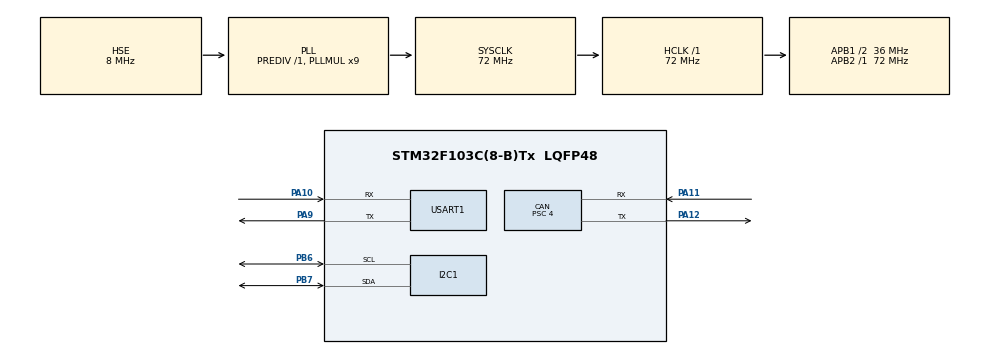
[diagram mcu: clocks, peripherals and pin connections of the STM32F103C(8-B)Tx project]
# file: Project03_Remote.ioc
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CAN.BS1=CAN_BS1_15TQ
CAN.BS2=CAN_BS2_2TQ
CAN.CalculateBaudRate=500000
CAN.CalculateTimeBit=2000
CAN.CalculateTimeQuantum=111.11111111111111
CAN.Prescaler=4
FREERTOS.Tasks01=defaultTask,0,128,StartDefaultTask,Default,NULL,Dynamic,NULL,NULL;CanRxTask,-3,256,StartCanRxTask,Default,NULL,Dynamic,NULL,NULL
FREERTOS.configTOTAL_HEAP_SIZE=6144
I2C1.I2C_Mode=I2C_Fast
Mcu.Family=STM32F1
Mcu.Name=STM32F103C(8-B)Tx
Mcu.Package=LQFP48
NVIC.PriorityGroup=NVIC_PRIORITYGROUP_4
NVIC.USB_LP_CAN1_RX0_IRQn=true\:5\:0\:false\:false\:true\:true\:true\:true\:true
PA10.Mode=Asynchronous
PA10.Signal=USART1_RX
PA11.Mode=CAN_Activate
PA11.Signal=CAN_RX
PA12.Mode=CAN_Activate
PA12.Signal=CAN_TX
PA13.Mode=Serial_Wire
PA13.Signal=SYS_JTMS-SWDIO
PA14.Mode=Serial_Wire
PA14.Signal=SYS_JTCK-SWCLK
PA9.Mode=Asynchronous
PA9.Signal=USART1_TX
PB6.Mode=I2C
PB6.Signal=I2C1_SCL
PB7.Mode=I2C
PB7.Signal=I2C1_SDA
PD0-OSC_IN.Mode=HSE-External-Oscillator
PD0-OSC_IN.Signal=RCC_OSC_IN
PD1-OSC_OUT.Mode=HSE-External-Oscillator
PD1-OSC_OUT.Signal=RCC_OSC_OUT
ProjectManager.HeapSize=0x200
ProjectManager.StackSize=0x400
ProjectManager.TargetToolchain=STM32CubeIDE
RCC.AHBFreq_Value=72000000
RCC.APB1CLKDivider=RCC_HCLK_DIV2
RCC.APB1Freq_Value=36000000
RCC.APB1TimFreq_Value=72000000
RCC.APB2Freq_Value=72000000
RCC.APB2TimFreq_Value=72000000
RCC.HCLKFreq_Value=72000000
RCC.PLLMUL=RCC_PLL_MUL9
RCC.PLLSourceVirtual=RCC_PLLSOURCE_HSE
RCC.SYSCLKFreq_VALUE=72000000
RCC.SYSCLKSource=RCC_SYSCLKSOURCE_PLLCLK
RCC.USBFreq_Value=72000000
USART1.VirtualMode=VM_ASYNC
VP_FREERTOS_VS_CMSIS_V1.Mode=CMSIS_V1
board=custom

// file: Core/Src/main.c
/* USER CODE BEGIN Header */
/**
  ******************************************************************************
  * @file           : main.c
  * @brief          : Main program body
  ******************************************************************************
  * @attention
  *
  * Copyright (c) 2026 STMicroelectronics.
  * All rights reserved.
  *
  * This software is licensed under terms that can be found in the LICENSE file
  * in the root directory of this software component.
  * If no LICENSE file comes with this software, it is provided AS-IS.
  *
  ******************************************************************************
  */
/* USER CODE END Header */
#include "main.h"
#include "cmsis_os.h"
#include "can.h"
#include "i2c.h"
#include "usart.h"
#include "gpio.h"

/* USER CODE BEGIN Includes */
#include <stdio.h>
/* USER CODE END Includes */

/* USER CODE BEGIN PD */
/* CAN 수신 원형 버퍼의 칸 수.
   인터럽트가 빠르게 받아 담아두고 태스크가 천천히 꺼내 가므로
   잠깐 몰리는 것만 견디면 되어 8칸이면 충분하다. */
#define CAN_RX_RING_SIZE   8u
/* USER CODE END PD */

/* USER CODE BEGIN PV */
/* ===== CAN 수신 원형 버퍼 =====
   수신 인터럽트(ISR)가 head 를 밀면서 쓰고,
   CanRxTask 가 tail 을 밀면서 읽는다.
   쓰는 쪽 하나, 읽는 쪽 하나뿐이므로(생산자 1 : 소비자 1)
   인터럽트를 잠그지 않아도 서로 충돌하지 않는다.
   인터럽트가 값을 바꾸는 변수들이므로 컴파일러가 레지스터에
   캐시해 두지 못하도록 전부 volatile 로 선언한다. */
static volatile CanRxFrame_t g_can_ring[CAN_RX_RING_SIZE];
static volatile uint16_t     g_can_head     = 0;  /* 인터럽트가 다음에 쓸 칸 */
static volatile uint16_t     g_can_tail     = 0;  /* 태스크가 다음에 읽을 칸 */
static volatile uint32_t     g_can_total    = 0;  /* 총 수신 개수 */
static volatile uint32_t     g_can_overflow = 0;  /* 버퍼가 꽉 차서 버린 개수 */

/* ===== 디버거 관찰용 진단 변수 (Live Expressions) =====
   USB-TTL 시리얼 어댑터가 없어 printf 출력을 볼 수 없을 때,
   STM32CubeIDE 의 Live Expressions 창(디버깅 중에 변수 값을 실시간으로 보는 기능)에
   아래 이름을 그대로 적어 넣으면 값이 보인다.

   주의 1) static 을 붙이지 않는다.
             static 은 "이 파일 안에서만 보이게 하라"는 뜻이라,
             디버거가 이름으로 변수를 못 찾는 경우가 생긴다.
   주의 2) volatile 은 반드시 붙인다.
             이것이 없으면 컴파일러가 "어차피 아무도 안 읽는 값"이라고 판단해
             대입 문장 자체를 지워버리거나 레지스터에만 담아두어
             메모리를 들여다보는 디버거에게는 엉뚱한 값이 보인다. */

/* I2C 스캔에서 응답한 장치 총 개수 */
volatile uint8_t  g_diag_i2c_found        = 0u;
/* 응답한 주소 목록 (최대 8개까지, 나머지 칸은 0) */
volatile uint8_t  g_diag_i2c_addr[8]      = {0u};
/* IMU 주소. 0x68 이 응답하면 0x68, 못 찾으면 0 */
volatile uint8_t  g_diag_imu_addr         = 0u;
/* WHO_AM_I(0x75) 레지스터에서 읽은 값. 못 읽으면 0xFF */
volatile uint8_t  g_diag_who_am_i         = 0xFFu;
/* 칩이 어떤 모델인지 판별한 결과 코드
     0 = 못 찾음
     1 = MPU-9250 (WHO_AM_I 값 0x71, 9축·나침반 있음)
     2 = MPU-9255 (WHO_AM_I 값 0x73, 9축·나침반 있음)
     3 = MPU-6500 (WHO_AM_I 값 0x70, 6축·나침반 없음)
     4 = MPU-6050 (WHO_AM_I 값 0x68, 6축·나침반 없음)
     9 = 알 수 없는 칩 */
volatile uint8_t  g_diag_imu_kind         = 0u;
/* I2C 스캔이 끝나면 1 이 된다 */
volatile uint8_t  g_diag_scan_done        = 0u;

/* CAN 총 수신 개수 */
volatile uint32_t g_diag_can_total        = 0u;
/* 마지막으로 받은 프레임의 ID */
volatile uint32_t g_diag_can_last_id      = 0u;
/* 마지막으로 받은 프레임의 데이터 길이 (0~8) */
volatile uint8_t  g_diag_can_last_dlc     = 0u;
/* 마지막으로 받은 프레임의 데이터 8바이트 */
volatile uint8_t  g_diag_can_last_data[8] = {0u};
/* 직전 1초 동안 받은 개수 */
volatile uint32_t g_diag_can_per_sec      = 0u;

/* ===== CAN 통신 장애 원인 판별용 진단 변수 =====
   수신이 전혀 안 될 때(g_diag_can_per_sec 가 계속 0),
   원인이 "MCU 안쪽 설정"인지 "바깥 배선·트랜시버·상대 노드"인지
   갈라내기 위한 값들이다. 전부 Live Expressions 로 관찰한다.
   앞의 진단 변수들과 같은 이유로 static 을 붙이지 않고 volatile 만 붙인다. */

/* HAL_CAN_Start() 가 성공해서 지금 정상 모드로 돌고 있으면 1, 아니면 0 */
volatile uint8_t  g_diag_can_started      = 0u;
/* 수신 필터 설정(HAL_CAN_ConfigFilter)이 성공했으면 1 */
volatile uint8_t  g_diag_can_filter_ok    = 0u;
/* 수신 인터럽트 켜기(HAL_CAN_ActivateNotification)가 성공했으면 1 */
volatile uint8_t  g_diag_can_notify_ok    = 0u;

/* ===== CAN_ESR(오류 상태 레지스터)에서 뽑아낸 값들 =====
   RM0008(STM32F1 참조매뉴얼)의 CAN_ESR 비트 배치는 다음과 같다.
     비트 31~24 : REC[7:0]  수신 오류 카운터
     비트 23~16 : TEC[7:0]  송신 오류 카운터
     비트  6~4  : LEC[2:0]  마지막 오류 코드
     비트  3    : (예약, 쓰지 않음)
     비트  2    : BOFF      버스오프 상태
     비트  1    : EPVF      오류 수동(Error Passive) 상태
     비트  0    : EWGF      오류 경고(Error Warning) 상태
   [확인 기록] 작업 지시서의 표에는 TEC 가 24~31비트, REC 가 16~23비트라고
   적혀 있었으나 이는 둘이 서로 뒤바뀐 것이다. RM0008 기준으로는 위가 맞다.
   그래서 값을 뽑아내는 코드도 TEC 는 16비트에서, REC 는 24비트에서
   잘라내도록 해 두었다(freertos.c 의 Can_UpdateErrorDiag 참고). */

/* 송신 오류 카운터 (ESR 비트 23~16).
   보낸 프레임이 실패할 때마다 8씩 오른다.
   아무도 응답(ACK)해 주지 않는 상황이면 순식간에 128 까지 치솟는다. */
volatile uint8_t  g_diag_can_tec          = 0u;
/* 수신 오류 카운터 (ESR 비트 31~24).
   받는 쪽에서 어긋난 프레임을 볼 때마다 오른다.
   상대가 아예 아무것도 안 보내면 이 값은 0 에서 그대로 멈춰 있다. */
volatile uint8_t  g_diag_can_rec          = 0u;
/* 마지막 오류 코드 (ESR 비트 6~4). 값의 뜻은 아래 표와 같다.
     0 = 오류 없음
     1 = 스터프 오류 (같은 값이 6비트 내리 나왔다.
                      두 노드의 통신 속도(보율)가 서로 다를 때 잘 난다)
     2 = 폼 오류     (프레임의 정해진 모양이 어긋났다)
     3 = ACK 오류    (응답해 주는 노드가 하나도 없다.
                      상대가 꺼져 있거나, 트랜시버·배선·종단저항 문제다)
     4 = 비트 리세시브 오류 (1 을 내보냈는데 버스에서는 0 으로 읽혔다)
     5 = 비트 도미넌트 오류 (0 을 내보냈는데 버스에서는 1 로 읽혔다.
                             보통 트랜시버가 안 물려 있거나 배선이 끊긴 경우다)
     6 = CRC 오류    (검사값이 어긋났다)
     7 = 소프트웨어가 직접 써 넣은 값 (하드웨어가 낸 오류가 아니다) */
volatile uint8_t  g_diag_can_lec          = 0u;
/* 버스오프 상태면 1 (ESR 비트 2).
   송신 오류가 255 를 넘어서 컨트롤러가 스스로 버스에서 빠져나간 상태다. */
volatile uint8_t  g_diag_can_boff         = 0u;
/* 오류 수동(Error Passive) 상태면 1 (ESR 비트 1) */
volatile uint8_t  g_diag_can_epvf         = 0u;
/* 오류 경고(Error Warning) 상태면 1 (ESR 비트 0) */
volatile uint8_t  g_diag_can_ewgf         = 0u;
/* ESR 레지스터를 가공하지 않은 원본값 그대로.
   위의 낱개 값들이 미덥지 않을 때 이 값을 직접 들여다보면 된다. */
volatile uint32_t g_diag_can_esr_raw      = 0u;
/* HAL_CAN_GetError() 가 알려주는, HAL 계층이 모아 둔 오류값 */
volatile uint32_t g_diag_can_hal_err      = 0u;

/* ===== 루프백 자기진단 결과 =====
   루프백은 트랜시버도 바깥 배선도 없이,
   자기가 내보낸 프레임을 자기가 되받아 보는 시험 모드다.
   여기서 성공(1)이 나오면 클럭·비트타이밍(통신 속도)·필터·인터럽트 같은
   MCU 안쪽 설정이 전부 정상이라는 뜻이고,
   남은 원인은 바깥(트랜시버·배선·종단저항·상대 노드)뿐으로 좁혀진다.
     0 = 아직 실행 안 함
     1 = 성공 (MCU 안쪽은 정상)
     2 = 송신 실패 (송신함에 프레임을 넣지 못했다)
     3 = 수신 타임아웃 (내보냈지만 100ms 안에 되돌아오지 않았다)
     4 = 시험용 프레임이 안 되돌아옴 (남의 프레임은 들어왔지만,
         내가 보낸 0x7FF 시험용 프레임은 100ms 안에 되돌아오지 않았다)
     5 = 수신함에서 꺼내기 실패 (수신함에 뭔가 들어오기는 했는데 꺼내는 데
         실패했고, 시험용 프레임도 끝내 되돌아오지 않았다. 3 과 달리
         "아무것도 안 왔다"가 아니므로 배선이 아니라 수신함을 다루는 쪽을 본다) */
volatile uint8_t  g_diag_can_loopback     = 0u;
/* 루프백 시험을 마치고 정상 모드로 되돌리는 데 성공했으면 1.
   이 값이 0 이면 이후 통신이 영영 안 되는 상태이므로 가장 먼저 확인해야 한다. */
volatile uint8_t  g_diag_can_restore_ok   = 0u;
/* 버스오프에서 소프트웨어로 되살리는 데 온전히 성공한 횟수.
   시도만 하고 실패한 것은 세지 않는다. 실패는 g_diag_can_stuck 이 알려 준다. */
volatile uint32_t g_diag_can_recover_cnt  = 0u;
/* CAN 손잡이(hcan)가 리셋 없이는 되살릴 수 없는 상태에 빠졌으면 1.
   HAL_CAN_Stop() 은 손잡이 상태가 LISTENING 일 때만, HAL_CAN_Start() 는
   READY 일 때만 실제로 하드웨어를 건드린다. 그 밖의 상태에서는 아무 일도
   하지 않고 곧바로 오류만 돌려준다. 그래서 한 번 어긋난 상태로 굳어 버리면
   1초마다 다시 시도해 봐야 매번 헛물만 켤 뿐이고, g_diag_can_recover_cnt 는
   조금도 늘지 않고 그 자리에 멈춰 있는다. 온전히 되살아난 횟수만 세는 값이라
   실패한 시도는 아무리 되풀이해도 반영되지 않기 때문이다.
   Live Expressions 로 지켜볼 때 g_diag_can_stuck 이 1 인데 이 값이 멈춰 있다고
   해서 이상할 것이 없다. "몇 번 시도했는가"가 아니라 "몇 번 되살아났는가"다.
     1 = 그렇게 굳어 버린 상태라 Stop/Start 를 아예 시도조차 못 했거나,
         시도는 했지만 실패했다는 뜻이다. 이때는 MCU 를 리셋해야 풀린다.
     0 = 그런 상태가 아니다.
   지금 형편을 그대로 비추는 값이라, 나중에 복구가 온전히 성공하면 다시 0 이 된다. */
volatile uint8_t  g_diag_can_stuck        = 0u;
/* USER CODE END PV */

void SystemClock_Config(void);
void MX_FREERTOS_Init(void);

int main(void)
{

  /* MCU Configuration--------------------------------------------------------*/

  /* Reset of all peripherals, Initializes the Flash interface and the Systick. */
  HAL_Init();

  /* Configure the system clock */
  SystemClock_Config();

  /* Initialize all configured peripherals */
  MX_GPIO_Init();
  MX_CAN_Init();
  MX_I2C1_Init();
  MX_USART1_UART_Init();
  /* USER CODE BEGIN 2 */
  /* printf 로 찍은 글자가 버퍼에 쌓여 있다가 화면에 안 나오는 일을 막는다.
     _IONBF 는 "버퍼를 쓰지 않는다"는 뜻으로, 한 글자 생길 때마다 바로 보낸다.
     진단용 코드에서는 보드가 멈춰버려도 그 직전까지 찍힌 내용이
     그대로 남아 있어야 원인을 찾을 수 있다. */
  setvbuf(stdout, NULL, _IONBF, 0);

  /* 부팅 배너 - 지금 켜진 보드가 어느 쪽인지 한눈에 알아보기 위한 것 */
  printf("\r\n========================================\r\n");
  printf(" Project03_Remote (조종 노드) 시작\r\n");
  printf(" CAN 500kbps / I2C1 400kHz / UART 115200\r\n");
  printf("========================================\r\n");

  /* ===== CAN 수신 필터 설정 =====
     마스크를 0으로 두면 ID 를 비교하는 자리가 하나도 없어져서
     결과적으로 모든 ID 가 통과한다.
     지금은 진단이 목적이라 버스에 실제로 어떤 ID 가 흐르고 있는지를
     눈으로 전부 확인해야 하므로 일부러 전부 통과시킨다. */
  CAN_FilterTypeDef can_filter = {0};
  can_filter.FilterBank           = 0;
  can_filter.FilterMode           = CAN_FILTERMODE_IDMASK;
  can_filter.FilterScale          = CAN_FILTERSCALE_32BIT;
  can_filter.FilterIdHigh         = 0x0000;
  can_filter.FilterIdLow          = 0x0000;
  can_filter.FilterMaskIdHigh     = 0x0000;   /* 마스크 0 = 전부 통과 */
  can_filter.FilterMaskIdLow      = 0x0000;
  can_filter.FilterFIFOAssignment = CAN_FILTER_FIFO0;
  can_filter.FilterActivation     = ENABLE;
  can_filter.SlaveStartFilterBank = 14;

  /* 아래 세 가지는 실패하더라도 Error_Handler() 로 보내지 않는다.
     Error_Handler() 는 인터럽트를 모두 끄고 무한루프에 갇히기 때문에,
     CAN 트랜시버를 연결하지 않은 채 전원을 켜면 보드가 통째로 먹통이 되어
     UART 로그조차 한 줄도 안 나온다. 그러면 무엇이 잘못됐는지 알 수 없다.
     그래서 실패했다는 사실만 화면에 알리고,
     나머지 진단(I2C 스캔 등)은 그대로 이어서 진행하도록 한다. */
  if (HAL_CAN_ConfigFilter(&hcan, &can_filter) != HAL_OK)
  {
    printf("[CAN] 필터 설정 실패 (그래도 계속 진행합니다)\r\n");
  }
  else
  {
    g_diag_can_filter_ok = 1u;   /* 디버거에서 볼 수 있게 성공 여부를 남긴다 */
  }
  if (HAL_CAN_Start(&hcan) != HAL_OK)
  {
    printf("[CAN] 시작 실패 - 트랜시버 연결과 배선을 확인하세요 (그래도 계속 진행합니다)\r\n");
  }
  else
  {
    g_diag_can_started = 1u;
  }
  if (HAL_CAN_ActivateNotification(&hcan, CAN_IT_RX_FIFO0_MSG_PENDING) != HAL_OK)
  {
    printf("[CAN] 수신 인터럽트 켜기 실패 (그래도 계속 진행합니다)\r\n");
  }
  else
  {
    g_diag_can_notify_ok = 1u;
    printf("[CAN] 준비 완료 - 모든 ID 를 통과시키는 필터로 대기합니다\r\n");
  }
  /* USER CODE END 2 */

  /* Call init function for freertos objects (in cmsis_os2.c) */
  MX_FREERTOS_Init();

  /* Start scheduler */
  osKernelStart();

  /* We should never get here as control is now taken by the scheduler */

  /* Infinite loop */
  while (1)
  {

  }
}

void SystemClock_Config(void)
{
  RCC_OscInitTypeDef RCC_OscInitStruct = {0};
  RCC_ClkInitTypeDef RCC_ClkInitStruct = {0};

  /** Initializes the RCC Oscillators according to the specified parameters
  * in the RCC_OscInitTypeDef structure.
  */
  RCC_OscInitStruct.OscillatorType = RCC_OSCILLATORTYPE_HSE;
  RCC_OscInitStruct.HSEState = RCC_HSE_ON;
  RCC_OscInitStruct.HSEPredivValue = RCC_HSE_PREDIV_DIV1;
  RCC_OscInitStruct.HSIState = RCC_HSI_ON;
  RCC_OscInitStruct.PLL.PLLState = RCC_PLL_ON;
  RCC_OscInitStruct.PLL.PLLSource = RCC_PLLSOURCE_HSE;
  RCC_OscInitStruct.PLL.PLLMUL = RCC_PLL_MUL9;
  if (HAL_RCC_OscConfig(&RCC_OscInitStruct) != HAL_OK)
  {
    Error_Handler();
  }

  /** Initializes the CPU, AHB and APB buses clocks
  */
  RCC_ClkInitStruct.ClockType = RCC_CLOCKTYPE_HCLK|RCC_CLOCKTYPE_SYSCLK
                              |RCC_CLOCKTYPE_PCLK1|RCC_CLOCKTYPE_PCLK2;
  RCC_ClkInitStruct.SYSCLKSource = RCC_SYSCLKSOURCE_PLLCLK;
  RCC_ClkInitStruct.AHBCLKDivider = RCC_SYSCLK_DIV1;
  RCC_ClkInitStruct.APB1CLKDivider = RCC_HCLK_DIV2;
  RCC_ClkInitStruct.APB2CLKDivider = RCC_HCLK_DIV1;

  if (HAL_RCC_ClockConfig(&RCC_ClkInitStruct, FLASH_LATENCY_2) != HAL_OK)
  {
    Error_Handler();
  }
}

/* USER CODE BEGIN 4 */
/**
  * @brief  printf 가 글자 하나를 내보낼 때 호출되는 함수.
  *         syscalls.c 안의 _write() 가 글자마다 이 함수를 부른다.
  *         여기서 USART1 로 실제 전송하므로, 이 함수만 있으면
  *         printf 출력이 디버그용 시리얼 창에 그대로 나타난다.
  */
int __io_putchar(int ch)
{
  /* ch 는 int 지만 실제로 보낼 것은 맨 아래 1바이트뿐이다 */
  HAL_UART_Transmit(&huart1, (uint8_t *)&ch, 1, 100);
  return ch;
}

/**
  * @brief  CAN 수신 FIFO0 에 프레임이 도착했을 때 자동으로 불리는 함수(인터럽트).
  *
  *         [중요] 이 안에서는 절대로 printf 를 부르지 않는다.
  *         printf 는 UART 로 한 글자씩 다 나갈 때까지 기다리는 방식이라
  *         인터럽트가 그만큼 오래 붙잡혀 있게 되고,
  *         그 사이에 들어온 다음 프레임을 놓쳐버린다.
  *         그래서 여기서는 원형 버퍼에 담아두고 개수만 세고 곧바로 빠져나오며,
  *         실제 화면 출력은 CanRxTask 가 여유 있을 때 대신 처리한다.
  */
void HAL_CAN_RxFifo0MsgPendingCallback(CAN_HandleTypeDef *hcan_arg)
{
  CAN_RxHeaderTypeDef header;
  uint8_t             rx_data[8];
  uint16_t            head;
  uint16_t            next;
  uint8_t             i;

  /* 하드웨어 수신함에서 프레임을 꺼낸다 */
  if (HAL_CAN_GetRxMessage(hcan_arg, CAN_RX_FIFO0, &header, rx_data) != HAL_OK)
  {
    return;
  }

  /* 총 수신 개수는 버퍼가 꽉 찼든 아니든 항상 센다 */
  g_can_total++;

  /* 디버거(Live Expressions)로 볼 진단용 값도 여기서 같이 갱신한다.
     인터럽트 안이므로 printf 는 절대 부르지 않고 단순 대입만 한다.
     아래는 원형 버퍼가 가득 차서 버리는 경우보다 앞에 두었다.
     버려지더라도 "버스에 지금 무엇이 흘러오는가"는 보여야 하기 때문이다. */
  g_diag_can_total    = g_can_total;
  g_diag_can_last_id  = (header.IDE == CAN_ID_STD) ? header.StdId : header.ExtId;
  g_diag_can_last_dlc = (uint8_t)header.DLC;
  for (i = 0u; i < 8u; i++)
  {
    g_diag_can_last_data[i] = rx_data[i];
  }

  head = g_can_head;
  next = (uint16_t)(head + 1u);
  if (next >= CAN_RX_RING_SIZE)
  {
    next = 0u;
  }

  if (next == g_can_tail)
  {
    /* 버퍼가 가득 찼다. 이번 프레임은 버리고 버린 개수만 따로 센다. */
    g_can_overflow++;
    return;
  }

  if (header.IDE == CAN_ID_STD)
  {
    g_can_ring[head].Id    = header.StdId;   /* 표준 11비트 ID */
    g_can_ring[head].IsExt = 0u;
  }
  else
  {
    g_can_ring[head].Id    = header.ExtId;   /* 확장 29비트 ID */
    g_can_ring[head].IsExt = 1u;
  }
  g_can_ring[head].Dlc = (uint8_t)header.DLC;

  for (i = 0u; i < 8u; i++)
  {
    g_can_ring[head].Data[i] = rx_data[i];
  }

  /* 내용을 다 채운 뒤에 마지막으로 head 를 옮긴다.
     읽는 쪽이 아직 덜 채워진 칸을 먼저 보게 되는 것을 막기 위한 순서다. */
  g_can_head = next;
}

/**
  * @brief  원형 버퍼에서 CAN 프레임을 하나 꺼낸다. (CanRxTask 전용)
  * @retval 1 = 하나 꺼냈음, 0 = 버퍼가 비어 있음
  */
uint8_t CanRx_Pop(CanRxFrame_t *out)
{
  uint16_t tail;
  uint8_t  i;

  if (out == NULL)
  {
    return 0u;
  }

  tail = g_can_tail;
  if (tail == g_can_head)
  {
    return 0u;   /* 비어 있음 */
  }

  /* volatile 인 버퍼에서 일반 변수로 한 항목씩 옮겨 담는다 */
  out->Id    = g_can_ring[tail].Id;
  out->IsExt = g_can_ring[tail].IsExt;
  out->Dlc   = g_can_ring[tail].Dlc;
  for (i = 0u; i < 8u; i++)
  {
    out->Data[i] = g_can_ring[tail].Data[i];
  }

  tail = (uint16_t)(tail + 1u);
  if (tail >= CAN_RX_RING_SIZE)
  {
    tail = 0u;
  }
  g_can_tail = tail;   /* 다 옮긴 뒤에 tail 을 옮긴다 */

  return 1u;
}

/**
  * @brief  부팅 후 지금까지 받은 CAN 프레임 총 개수를 알려준다.
  */
uint32_t CanRx_GetTotal(void)
{
  return g_can_total;
}

/**
  * @brief  원형 버퍼가 가득 차서 버려진 프레임 개수를 알려준다.
  *         이 값이 계속 늘어난다면 출력이 수신 속도를 못 따라가고 있다는 뜻이다.
  */
uint32_t CanRx_GetOverflow(void)
{
  return g_can_overflow;
}
/* USER CODE END 4 */

void Error_Handler(void)
{
  __disable_irq();
  while (1)
  {
  }
}

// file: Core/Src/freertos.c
/* USER CODE BEGIN Header */
/**
  ******************************************************************************
  * File Name          : freertos.c
  * Description        : Code for freertos applications
  ******************************************************************************
  * @attention
  *
  * Copyright (c) 2026 STMicroelectronics.
  * All rights reserved.
  *
  * This software is licensed under terms that can be found in the LICENSE file
  * in the root directory of this software component.
  * If no LICENSE file comes with this software, it is provided AS-IS.
  *
  ******************************************************************************
  */
/* USER CODE END Header */

#include "FreeRTOS.h"
#include "task.h"
#include "main.h"
#include "cmsis_os.h"

/* USER CODE BEGIN Includes */
#include <stdio.h>
#include "i2c.h"
/* CAN 손잡이(hcan)와 CAN 관련 HAL 함수들을 쓰기 위해 필요하다 */
#include "can.h"
/* MPU-9255 자세 추정(초기화 / 한 걸음 갱신 / 각도 읽기)을 쓰기 위해 필요하다 */
#include "mpu9255.h"
/* USER CODE END Includes */

/* USER CODE BEGIN PD */
/* I2C 버스를 훑어볼 주소 범위 (7비트 주소 체계에서 쓸 수 있는 전 구간) */
#define I2C_SCAN_ADDR_MIN        1u
#define I2C_SCAN_ADDR_MAX        127u

/* 같은 모듈에 함께 붙어 나오는 경우가 많은 기압 센서 주소 */
#define BMP280_ADDR_7BIT         0x76u

/* CAN 프레임을 화면에 찍는 최소 간격(밀리초).
   상대 노드가 100ms 마다 보내므로 전부 찍으면 화면이 순식간에 넘쳐서
   정작 봐야 할 내용을 놓친다. 500ms 간격 = 초당 2개만 찍는다. */
#define CAN_PRINT_INTERVAL_MS    500u

/* IMU 자세(좌우/앞뒤 기울기)를 실어 보내는 CAN 프레임의 식별자.
   이 프로젝트에는 메시지 번호를 모아 둔 헤더 계층이 따로 없어서
   식별자를 이렇게 파일 안의 정의로 두고 쓴다(루프백 시험의 0x7FF 와 같은 방식).
   받는 쪽(vehicle)도 똑같이 0x120 으로 맞춰 두었으므로 함부로 바꾸면 안 된다. */
#define CAN_ID_IMU_ATTITUDE      0x120u

/* IMU 태스크가 몇 번 돌 때마다 한 번 CAN 으로 내보낼지.
   20ms 주기로 다섯 번에 한 번이므로 100ms 마다 한 프레임이 나간다.
   시작 알림에 찍는 주기와 실제로 세는 값이 이 하나를 같이 보게 해 두어,
   한쪽만 고쳐서 둘이 소리 없이 어긋나는 일을 막는다. */
#define IMU_TX_DIVIDER           5u
/* USER CODE END PD */

/* USER CODE BEGIN Variables */
/* IMU 태스크의 손잡이.
   [바로 아래 defaultTaskHandle 옆에 두지 않고 굳이 여기에 두는 이유]
   아래 두 줄은 CubeMX 가 직접 만들어 관리하는 자리라 USER CODE 구역 밖이다.
   그 옆에 끼워 넣으면 다시 만들기(Generate Code) 한 번에 소리 없이 사라진다.
   여기 Variables 구역은 CubeMX 가 건드리지 않고 지켜 주는 자리다. */
osThreadId ImuTaskHandle;

/* I2C 버스 사용권을 넘겨주는 신호(이진 세마포어)의 손잡이.

   [무엇을 막으려고 두는가]
   StartDefaultTask 는 부팅 때 127개 주소를 두드리는 I2C 스캔과 그 뒤의 WHO_AM_I
   읽기를 하고, StartImuTask 는 Mpu9255_Init() 안에서 자기 나름의 I2C 쓰기/읽기와
   약 1초짜리 자이로 영점 측정을 한다. 두 태스크는 우선순위가 똑같이 Normal 이고
   osKernelStart() 와 동시에 나란히 깨어나므로, 같은 hi2c1 을 진짜로 동시에 붙잡는다.
   HAL 이 그것을 막으라고 둔 __HAL_LOCK 은 "잠겨 있나 보고 -> 잠근다"를 두 걸음으로
   나눠서 하는 코드라, 그 사이에서 태스크가 갈리면 둘 다 자기가 주인이라고 믿는다.
   그러면 얌전한 HAL_BUSY 가 돌아오는 것이 아니라 전송 자체가 깨지거나 버스가 물린다.
   (이 프로젝트가 가져다 쓰는 stm32f1xx_hal_def.h 는 그 잠금장치 위에
    #error "USE_RTOS should be 0" 까지 달아 두었다. RTOS 와 같이 쓰라고 만든
    물건이 아니라고 벤더가 직접 못을 박아 둔 것이다.)
   그래서 잠금으로 겹침을 "정리"하려 들지 않고, 애초에 겹치지 않도록 순서를 세운다.

   [ImuTaskHandle 과 나란히 여기에 두는 이유]
   위와 같은 사정이다. 아래 두 줄은 CubeMX 가 직접 만들어 관리하는 자리라,
   그 옆에 끼워 넣으면 다시 만들기(Generate Code) 한 번에 소리 없이 사라진다. */
static osSemaphoreId s_i2cScanDoneSem = NULL;
/* USER CODE END Variables */
osThreadId defaultTaskHandle;
osThreadId CanRxTaskHandle;

/* USER CODE BEGIN FunctionPrototypes */
/* 모든 ID 를 통과시키는 수신 필터를 설정한다.
   루프백 시험 전과 정상 모드 복귀 때 두 번 쓰이므로 함수로 묶어 두었다.
   반환값 1 = 성공, 0 = 실패 */
static uint8_t Can_SetAcceptAllFilter(void);

/* 표준 ID 프레임 하나를 송신함에 넣는다. 송신함에 빈자리가 없으면 기다리지 않고
   곧바로 실패를 돌려준다(이 파일의 송신은 전부 주기적 알림이라 다음 것이 곧 온다).
   루프백 시험과 IMU 태스크 두 곳에서 쓰므로 함수로 묶었다.
   반환값 1 = 송신함에 넣었음, 0 = 넣지 못했음 */
static uint8_t Can_Send(uint32_t stdId, const uint8_t *data, uint8_t dlc);

/* CAN 컨트롤러 자체가 멀쩡한지 바깥 배선과 무관하게 확인하는 자기진단.
   결과는 g_diag_can_loopback 과 g_diag_can_restore_ok 에 담긴다. */
static void Can_LoopbackSelfTest(void);

/* CAN_ESR(오류 상태 레지스터)를 읽어 진단 변수들을 갱신한다. */
static void Can_UpdateErrorDiag(void);

/* 버스오프에 빠졌으면 CAN 을 껐다 켜서 되살려 본다.
   반환값 0 = 버스오프가 아니어서 할 일이 없었음,
          1 = 이번에 온전히 되살아났음,
          2 = 시도했지만(또는 시도조차 못 하고) 실패했음 */
static uint8_t Can_TryBusOffRecover(void);

/* IMU 태스크 본체. 20ms 마다 센서를 읽어 자세를 갱신하고,
   그 가운데 다섯 번에 한 번(=100ms)씩 자세를 CAN 으로 내보낸다.
   osThreadDef() 가 이 이름을 그대로 가져다 쓰므로 static 으로 두면 안 된다. */
void StartImuTask(void const * argument);
/* USER CODE END FunctionPrototypes */

void StartDefaultTask(void const * argument);
void StartCanRxTask(void const * argument);

void MX_FREERTOS_Init(void); /* (MISRA C 2004 rule 8.1) */

/* GetIdleTaskMemory prototype (linked to static allocation support) */
void vApplicationGetIdleTaskMemory( StaticTask_t **ppxIdleTaskTCBBuffer, StackType_t **ppxIdleTaskStackBuffer, uint32_t *pulIdleTaskStackSize );

/* USER CODE BEGIN GET_IDLE_TASK_MEMORY */
static StaticTask_t xIdleTaskTCBBuffer;
static StackType_t xIdleStack[configMINIMAL_STACK_SIZE];

void vApplicationGetIdleTaskMemory( StaticTask_t **ppxIdleTaskTCBBuffer, StackType_t **ppxIdleTaskStackBuffer, uint32_t *pulIdleTaskStackSize )
{
  *ppxIdleTaskTCBBuffer = &xIdleTaskTCBBuffer;
  *ppxIdleTaskStackBuffer = &xIdleStack[0];
  *pulIdleTaskStackSize = configMINIMAL_STACK_SIZE;
  /* place for user code */
}
/* USER CODE END GET_IDLE_TASK_MEMORY */

void MX_FREERTOS_Init(void) {

  /* USER CODE BEGIN RTOS_SEMAPHORES */
  /* add semaphores, ... */

  /* I2C 버스 사용권 신호를 만든다.
     (두 태스크가 왜 겹치면 안 되는지는 파일 위쪽 s_i2cScanDoneSem 선언부에 적었다.)

     [왜 하필 이 자리인가]
     MX_FREERTOS_Init() 은 스케줄러가 돌기 전에, 그리고 바로 아래에서 태스크들을
     만들기도 전에 불린다. 그래서 두 태스크 중 어느 쪽이 먼저 깨어나 이 손잡이를
     들여다보든 이미 값이 채워져 있는 것이 보장된다. 태스크 안에서 만들었다면
     "누가 먼저 깨어나느냐"에 따라 아직 NULL 인 손잡이를 보게 되어,
     겹침을 막으려고 둔 장치가 도리어 또 하나의 경쟁거리가 될 뻔했다.

     [개수를 1 로 두는 이유]
     이 프로젝트의 FreeRTOSConfig.h 에는 configUSE_COUNTING_SEMAPHORES 가 없다.
     그래서 osSemaphoreCreate() 에 1 이 아닌 개수를 주면 세는 세마포어를 만드는
     쪽으로 갔다가 아무것도 못 만들고 NULL 만 돌아온다.
     1 은 취향으로 고른 값이 아니라 여기서 유일하게 쓸 수 있는 값이다.

     [만들자마자 한 번 가져가는 줄이 반드시 있어야 하는 이유]
     개수 1 짜리는 안에서 vSemaphoreCreateBinary() 로 만들어지는데, 이 방식은
     세마포어를 "토큰이 이미 하나 놓여 있는" 상태로 내놓는다. 그 토큰을 여기서
     미리 치워 두지 않으면 StartImuTask 의 기다림이 첫 줄에서 그냥 통과해 버려,
     순서 세우기가 아무 일도 하지 않는 껍데기가 된다. 겉보기에는 고친 것 같은데
     실제로는 예전 그대로 겹치는, 가장 알아채기 어려운 모양이 되는 것이다.
     기다림 없이(0 틱) 가져가는 것이라 스케줄러가 아직 안 도는 여기서도 안전하다. */
  osSemaphoreDef(I2cScanDoneSem);
  s_i2cScanDoneSem = osSemaphoreCreate(osSemaphore(I2cScanDoneSem), 1);
  if (s_i2cScanDoneSem != NULL)
  {
    (void)osSemaphoreWait(s_i2cScanDoneSem, 0);
  }
  /* USER CODE END RTOS_SEMAPHORES */

  /* Create the thread(s) */
  /* definition and creation of defaultTask */
  osThreadDef(defaultTask, StartDefaultTask, osPriorityNormal, 0, 128);
  defaultTaskHandle = osThreadCreate(osThread(defaultTask), NULL);

  /* definition and creation of CanRxTask */
  osThreadDef(CanRxTask, StartCanRxTask, osPriorityIdle, 0, 256);
  CanRxTaskHandle = osThreadCreate(osThread(CanRxTask), NULL);

  /* USER CODE BEGIN RTOS_THREADS */
  /* add threads, ... */

  /* IMU 자세 추정 태스크.
     [우선순위를 Normal 로 두는 이유]
     20ms 라는 정해진 간격으로 표본을 떠야 자이로 적분이 맞는다.
     CanRxTask(osPriorityIdle) 처럼 낮게 두면 다른 태스크에 계속 밀려
     간격이 들쭉날쭉해지고, 그만큼 각도가 실제와 어긋난다.
     [스택을 256(워드)로 두는 이유]
     이 칩에는 부동소수점 계산기가 없어서 float 연산이 전부 함수 호출로 풀린다.
     atan2f / sqrtf 는 그 안에서 다시 여러 겹으로 파고들며 스택을 꽤 쓴다.
     기본값 128 로는 아슬아슬해서, 넉넉하게 CanRxTask 와 같은 256 으로 잡았다. */
  osThreadDef(ImuTask, StartImuTask, osPriorityNormal, 0, 256);
  ImuTaskHandle = osThreadCreate(osThread(ImuTask), NULL);
  /* USER CODE END RTOS_THREADS */

}

void StartDefaultTask(void const * argument)
{
  /* USER CODE BEGIN StartDefaultTask */
  uint8_t      addr;
  uint8_t      found_count = 0u;   /* 응답한 장치 개수 */
  uint8_t      mpu_found   = 0u;   /* 0x68 이 응답했는지 여부 */
  uint8_t      who_am_i    = 0u;
  const char  *chip_name;
  uint32_t     total;
  uint32_t     prev_total  = 0u;   /* 1초 전의 총 수신 개수 */

  /* ================= CAN 루프백 자기진단 (부팅 후 딱 한 번만) =================
     [왜 여기인가]
       1) 이 자리는 FreeRTOS 스케줄러가 이미 돌기 시작한 뒤라서
          osDelay() 를 쓸 수 있다. main() 안이었다면 스케줄러가 아직 안 돌아
          osDelay() 가 먹히지 않아 HAL_Delay() 를 써야 했을 것이다.
       2) I2C 스캔보다 앞에 두었다. 스캔은 127개 주소를 하나씩 두드리느라
          1초 넘게 걸리는데, 그 뒤로 미루면 진단 결과가 그만큼 늦게 나온다.
       3) 루프백 시험을 하는 동안에는 바깥에서 들어오는 진짜 프레임을 받지 못한다.
          그러니 이 "못 받는 구간"은 부팅 직후로 최대한 당겨서 짧게 끝내는 편이 낫다. */
  Can_LoopbackSelfTest();

  /* ================= I2C 버스 스캔 (부팅 후 딱 한 번만) ================= */
  printf("[I2C] 버스 스캔을 시작합니다 (주소 0x01 ~ 0x7F)\r\n");

  for (addr = I2C_SCAN_ADDR_MIN; addr <= I2C_SCAN_ADDR_MAX; addr++)
  {
    /* HAL 함수는 8비트 형태의 주소를 받는다.
       7비트 주소의 오른쪽 한 칸은 읽기/쓰기 구분용 자리이므로,
       7비트 주소를 왼쪽으로 한 칸 밀어서(addr << 1) 넘겨야 한다.
       이걸 빼먹으면 실제로는 절반 주소로 두드리게 되어 아무것도 못 찾는다. */
    if (HAL_I2C_IsDeviceReady(&hi2c1, (uint16_t)(addr << 1), 2, 10) == HAL_OK)
    {
      found_count++;

      /* 디버거(Live Expressions)로 볼 진단 변수에도 같은 내용을 담아 둔다.
         주소 목록 배열은 8칸뿐이므로, 그 안에 들어갈 때만 기록한다(경계 검사).
         9개째부터는 개수만 늘어나고 목록에는 담기지 않는다. */
      if (found_count <= 8u)
      {
        g_diag_i2c_addr[found_count - 1u] = addr;
      }
      g_diag_i2c_found = found_count;

      if (addr == MPU9255_ADDR_7BIT)
      {
        mpu_found = 1u;
        g_diag_imu_addr = MPU9255_ADDR_7BIT;   /* IMU 를 이 주소에서 찾았다 */
        printf("[I2C]   0x%02X 응답  <- 9축 IMU 로 보입니다\r\n", (unsigned int)addr);
      }
      else if (addr == BMP280_ADDR_7BIT)
      {
        printf("[I2C]   0x%02X 응답  <- 기압 센서(BMP280) 로 보입니다\r\n", (unsigned int)addr);
      }
      else
      {
        printf("[I2C]   0x%02X 응답\r\n", (unsigned int)addr);
      }
    }

    /* 주소 하나를 두드릴 때마다 잠깐 자리를 내준다.
       HAL_I2C_IsDeviceReady() 는 응답이 올 때까지 붙잡고 있는 함수라,
       이 태스크(osPriorityNormal)가 127개 주소를 내리 두드리는 동안
       우선순위가 낮은 CanRxTask(osPriorityIdle)는 아예 돌지 못한다.
       그동안 들어온 CAN 프레임은 아무도 꺼내 가지 않아 원형 버퍼에 쌓이기만 하고,
       버퍼가 꽉 차면 그 뒤 프레임은 그냥 버려진다.
       그래서 부팅 중에 들어온 CAN 프레임이 소리 없이 사라진다.
       여기서 1ms 씩 자리를 넘겨 주면 CanRxTask 가 그 틈에 버퍼를 비워 낼 수 있다.
       스캔 전체가 127ms 쯤 길어지지만, 프레임을 잃는 것보다는 낫다. */
    osDelay(1);
  }

  printf("[I2C] 스캔 완료: 모두 %u개 장치가 응답했습니다\r\n", (unsigned int)found_count);

  if (found_count == 0u)
  {
    /* 하나도 못 찾았을 때는 어디를 봐야 하는지 순서대로 알려준다 */
    printf("[I2C] 응답한 장치가 하나도 없습니다. 아래를 확인해 주세요.\r\n");
    printf("[I2C]   1) SCL 은 PB6, SDA 는 PB7 입니다. 두 선이 서로 바뀌지 않았는지 보세요.\r\n");
    printf("[I2C]   2) 센서 모듈의 VCC(3.3V) 와 GND 가 제대로 꽂혀 있는지 보세요.\r\n");
    printf("[I2C]   3) MPU-9250 모듈의 NCS 핀은 I2C 로 쓸 때 3.3V 에 연결해야 합니다.\r\n");
    printf("[I2C]      (NCS 가 GND 나 빈 상태면 SPI 모드로 잡혀 I2C 로는 응답하지 않습니다)\r\n");
    printf("[I2C]   4) AD0 핀이 GND 면 주소가 0x68, 3.3V 면 0x69 가 됩니다.\r\n");
    printf("[I2C]   5) 신호선을 3.3V 로 끌어올리는 풀업 저항이 있는지 보세요.\r\n");
  }
  else if (mpu_found != 0u)
  {
    /* 0x68 이 응답했으니 어떤 칩인지 WHO_AM_I 레지스터를 읽어 확인한다.
       이 레지스터에는 칩마다 고유한 값이 들어 있어 모델 구분이 가능하다.
       주소와 레지스터 번호는 드라이버(mpu9255.h)의 정의를 그대로 쓰지만 읽기는 일부러 여기서 직접 한다.
       이 스캔은 Mpu9255_Init() 보다 먼저 도는 부팅 과정이라 드라이버는 아직 알려줄 것이 없기 때문이다. */
    if (HAL_I2C_Mem_Read(&hi2c1, (uint16_t)(MPU9255_ADDR_7BIT << 1),
                         MPU9255_REG_WHO_AM_I, I2C_MEMADD_SIZE_8BIT,
                         &who_am_i, 1, 100) == HAL_OK)
    {
      /* 읽은 값 그대로를 디버거로 볼 수 있게 남긴다 */
      g_diag_who_am_i = who_am_i;

      /* 화면에 찍을 이름과, 디버거로 볼 판별 코드를 함께 정한다.
         (판별 코드의 의미는 main.h / main.c 의 선언부에 적어 두었다) */
      switch (who_am_i)
      {
        case 0x71u: chip_name = "MPU-9250 (9축, 나침반 있음)";
                    g_diag_imu_kind = 1u;   /* 1 = MPU-9250 */
                    break;
        case 0x73u: chip_name = "MPU-9255 (9축, 나침반 있음)";
                    g_diag_imu_kind = 2u;   /* 2 = MPU-9255 */
                    break;
        case 0x70u: chip_name = "MPU-6500 (6축, 나침반 없음)";
                    g_diag_imu_kind = 3u;   /* 3 = MPU-6500 */
                    break;
        case 0x68u: chip_name = "MPU-6050 (6축, 나침반 없음)";
                    g_diag_imu_kind = 4u;   /* 4 = MPU-6050 */
                    break;
        default:    chip_name = "알 수 없는 칩";
                    g_diag_imu_kind = 9u;   /* 9 = 알 수 없는 칩 */
                    break;
      }
      printf("[IMU] WHO_AM_I(0x%02X) = 0x%02X -> %s\r\n",
             (unsigned int)MPU9255_REG_WHO_AM_I,
             (unsigned int)who_am_i, chip_name);
    }
    else
    {
      /* 읽기에 실패했다는 사실 자체를 디버거로 구분할 수 있게 표시한다.
         0xFF 는 "읽지 못했다"는 뜻으로 쓰는 값이다. */
      g_diag_who_am_i = 0xFFu;
      g_diag_imu_kind = 0u;   /* 0 = 못 찾음 */
      printf("[IMU] 0x68 은 응답했지만 WHO_AM_I 레지스터를 읽지 못했습니다\r\n");
    }
  }
  else
  {
    printf("[IMU] 0x68 주소에서 응답이 없습니다. AD0 핀이 3.3V 라면 주소는 0x69 입니다\r\n");
  }

  /* 여기까지 왔다면 I2C 스캔과 칩 판별이 모두 끝난 것이다.
     디버거에서 이 값이 1 이 되어야 위의 진단 변수들을 믿고 읽을 수 있다.
     계속 0 이라면 스캔 도중에 멈춰 있다는 뜻이다. */
  g_diag_scan_done = 1u;

  /* 이제 I2C 버스 사용권을 IMU 태스크에 넘긴다.

     [왜 하필 이 줄인가]
     이 자리는 127개 주소를 두드리는 스캔 고리와, 그 뒤 0x68 갈래에서 하는
     WHO_AM_I 읽기를 모두 지나온 지점이다. 즉 이 태스크가 hi2c1 을 건드리는
     마지막 일까지 끝난 자리라, 여기서 넘겨야 겹치는 순간이 한 톨도 남지 않는다.
     한 줄이라도 위로 올리면 아직 안 끝난 I2C 접근과 IMU 초기화가 겹친다.
     맨 위의 CAN 루프백 자기진단도 이 지점보다 앞에 있으므로, IMU 태스크는
     이 신호 하나만 기다리면 부팅 절차 전체가 끝나기를 기다리는 셈이 된다.
     반대로 더 뒤로 미룰 이유도 없다. 아래 1초 주기 고리는 CAN 만 들여다볼 뿐
     I2C 는 두 번 다시 건드리지 않으므로, 미뤄 봐야 IMU 시작만 늦어진다.

     손잡이가 NULL 이면 애초에 만들어지지 못한 것이고, 그때는 IMU 태스크가
     g_diag_scan_done 을 대신 지켜보도록 해 두었으므로 여기서 할 일이 없다. */
  if (s_i2cScanDoneSem != NULL)
  {
    (void)osSemaphoreRelease(s_i2cScanDoneSem);
  }

  printf("----------------------------------------\r\n");
  printf("[알림] 이제부터 1초마다 CAN 수신 현황을 알려드립니다\r\n");

  /* ================= 1초마다 CAN 수신 현황 요약 ================= */
  /* Infinite loop */
  for(;;)
  {
    osDelay(1000);

    /* ---------- CAN 오류 상태를 매초 새로 읽어 둔다 ---------- */
    Can_UpdateErrorDiag();

    /* ---------- 버스오프 자동 복구 ----------
       자세한 사정은 Can_TryBusOffRecover() 의 설명에 적어 두었다.
       돌려주는 값은 여기서 쓰지 않는다. 알림과 진단 변수 갱신은
       그 함수가 안에서 다 마치기 때문이다. */
    (void)Can_TryBusOffRecover();

    total = CanRx_GetTotal();

    /* 직전 1초 동안 늘어난 개수를 디버거로 볼 수 있게 담아 둔다.
       이 값이 0 이면 상대 노드가 안 보내고 있거나 배선 문제이고,
       정상이라면 상대가 100ms 주기로 보내므로 10 안팎이 나와야 한다. */
    g_diag_can_per_sec = total - prev_total;

    /* 총 개수와, 직전 1초 동안 늘어난 개수를 같이 보여준다.
       늘어난 개수가 0 이면 상대 노드가 안 보내고 있거나 배선 문제다.
       정상이라면 100ms 주기이므로 1초에 약 10개씩 늘어야 한다. */
    printf("[CAN 요약] 총 %lu개 수신 (최근 1초 +%lu개), 버퍼가 꽉 차 버린 것 %lu개\r\n",
           (unsigned long)total,
           (unsigned long)(total - prev_total),
           (unsigned long)CanRx_GetOverflow());

    prev_total = total;
  }
  /* USER CODE END StartDefaultTask */
}

void StartCanRxTask(void const * argument)
{
  /* USER CODE BEGIN StartCanRxTask */
  CanRxFrame_t frame;
  uint8_t      i;
  uint32_t     now;
  uint32_t     last_print_tick;

  /* [참고] 이 태스크는 지금 우선순위가 osPriorityIdle(-3) 로 잡혀 있다.
     이는 시스템에서 가장 낮은 등급이라, 다른 태스크가 바쁘면
     이 태스크는 계속 뒤로 밀려 CAN 출력이 끊기거나 늦게 나올 수 있다.
     지금은 진단용이고 출력이 조금 늦어도 상관없어서 그대로 두지만,
     나중에 실제 주행 제어 로직을 이 태스크에 붙일 때에는
     CubeMX 에서 osPriorityNormal 이상으로 반드시 올려주는 것이 좋다.
     (우선순위 설정은 CubeMX 가 만드는 자리라 코드에서 고치지 않았다) */

  /* 처음 들어온 프레임은 기다리지 않고 바로 찍히도록 시작값을 맞춰 둔다 */
  last_print_tick = osKernelSysTick() - CAN_PRINT_INTERVAL_MS;

  /* Infinite loop */
  for(;;)
  {
    /* 버퍼에 쌓인 프레임을 남김없이 꺼내 비운다.
       꺼내지 않고 두면 버퍼가 금방 가득 차서 새 프레임을 놓치게 된다. */
    while (CanRx_Pop(&frame) != 0u)
    {
      now = osKernelSysTick();

      /* 출력 속도 제한.
         상대가 100ms 마다 보내므로 받은 것을 전부 찍으면 화면이 넘쳐
         정작 봐야 할 내용을 놓친다. 그래서 500ms 에 한 개만 찍고
         나머지는 화면에 안 찍고 버린다.
         단, 몇 개를 받았는지 세는 일은 수신 인터럽트에서 계속 하고 있으므로
         여기서 안 찍어도 개수는 하나도 빠지지 않는다.
         (115200bps 라 여유는 있지만 그래도 제한을 두는 편이 안전하다) */
      if ((uint32_t)(now - last_print_tick) >= CAN_PRINT_INTERVAL_MS)
      {
        last_print_tick = now;

        if (frame.IsExt != 0u)
        {
          printf("[CAN] ID=0x%08lX(확장) DLC=%u data=",
                 (unsigned long)frame.Id, (unsigned int)frame.Dlc);
        }
        else
        {
          printf("[CAN] ID=0x%03lX DLC=%u data=",
                 (unsigned long)frame.Id, (unsigned int)frame.Dlc);
        }

        for (i = 0u; i < frame.Dlc; i++)
        {
          printf("%02X", (unsigned int)frame.Data[i]);
          if ((uint8_t)(i + 1u) < frame.Dlc)
          {
            printf(" ");   /* 바이트 사이만 띄우고 줄 끝에는 공백을 남기지 않는다 */
          }
        }
        printf("\r\n");
      }
    }

    /* 버퍼가 비었으면 잠깐 쉰다.
       FreeRTOS 환경이므로 HAL_Delay() 가 아니라 osDelay() 를 써야 한다.
       osDelay() 는 쉬는 동안 다른 태스크에 자리를 넘겨주지만,
       HAL_Delay() 는 자리를 넘기지 않고 그 자리에서 계속 붙잡고 있는다. */
    osDelay(10);
  }
  /* USER CODE END StartCanRxTask */
}

/* USER CODE BEGIN Application */
/**
  * @brief  모든 ID 를 통과시키는 수신 필터를 설정한다.
  *         마스크를 0 으로 두면 ID 를 비교하는 자리가 하나도 없어져
  *         결과적으로 어떤 ID 든 전부 통과한다.
  *         지금은 원인을 찾는 것이 목적이라, 버스에 실제로 어떤 ID 가
  *         흘러다니는지 하나도 빠짐없이 봐야 하므로 일부러 전부 통과시킨다.
  * @retval 1 = 성공, 0 = 실패
  */
static uint8_t Can_SetAcceptAllFilter(void)
{
  CAN_FilterTypeDef can_filter = {0};

  can_filter.FilterBank           = 0;
  can_filter.FilterMode           = CAN_FILTERMODE_IDMASK;
  can_filter.FilterScale          = CAN_FILTERSCALE_32BIT;
  can_filter.FilterIdHigh         = 0x0000;
  can_filter.FilterIdLow          = 0x0000;
  can_filter.FilterMaskIdHigh     = 0x0000;   /* 마스크 0 = 전부 통과 */
  can_filter.FilterMaskIdLow      = 0x0000;
  can_filter.FilterFIFOAssignment = CAN_FILTER_FIFO0;
  can_filter.FilterActivation     = ENABLE;
  can_filter.SlaveStartFilterBank = 14;

  if (HAL_CAN_ConfigFilter(&hcan, &can_filter) != HAL_OK)
  {
    g_diag_can_filter_ok = 0u;
    return 0u;
  }

  g_diag_can_filter_ok = 1u;
  return 1u;
}

/**
  * @brief  표준 ID 프레임 하나를 송신함에 넣는다.
  *
  *         [빈자리가 날 때까지 기다리지 않는 이유]
  *         이 파일에서 내보내는 것은 전부 주기적으로 되풀이되는 알림용 프레임이라
  *         다음 것이 곧 또 온다. 빈자리를 기다리며 여기서 붙잡고 있으면
  *         부르는 쪽의 주기가 통째로 밀려, 정작 더 중요한 일(IMU 라면 20ms 마다의
  *         자이로 적분)이 어긋난다. 버스가 막혀서 송신함이 찬 것이라면
  *         여기서 버틴다고 풀릴 문제도 아니다.
  *         그러니 이번 차례는 깨끗이 포기하고 부르는 쪽에 그대로 알린다.
  * @param  stdId : 표준 11비트 식별자
  * @param  data  : 실어 보낼 바이트들
  * @param  dlc   : 실어 보낼 바이트 수 (0 ~ 8)
  * @retval 1 = 송신함에 넣었음, 0 = 넣지 못했음
  */
static uint8_t Can_Send(uint32_t stdId, const uint8_t *data, uint8_t dlc)
{
  CAN_TxHeaderTypeDef tx_header  = {0};
  uint32_t            tx_mailbox = 0u;

  if (HAL_CAN_GetTxMailboxesFreeLevel(&hcan) == 0u)
  {
    return 0u;
  }

  tx_header.StdId              = stdId;
  tx_header.ExtId              = 0x0000u;
  tx_header.IDE                = CAN_ID_STD;
  tx_header.RTR                = CAN_RTR_DATA;
  tx_header.DLC                = dlc;
  tx_header.TransmitGlobalTime = DISABLE;

  if (HAL_CAN_AddTxMessage(&hcan, &tx_header, data, &tx_mailbox) != HAL_OK)
  {
    return 0u;
  }

  return 1u;
}

/**
  * @brief  CAN_ESR(오류 상태 레지스터)를 읽어 진단 변수들을 갱신한다.
  *         이 레지스터를 통째로 읽어오는 HAL 함수는 따로 없어서
  *         hcan.Instance->ESR 로 직접 읽는다.
  */
static void Can_UpdateErrorDiag(void)
{
  uint32_t esr;

  esr = hcan.Instance->ESR;
  g_diag_can_esr_raw = esr;

  /* RM0008(STM32F1 참조매뉴얼)의 CAN_ESR 비트 배치대로 잘라낸다.
       비트 0     = EWGF (오류 경고)
       비트 1     = EPVF (오류 수동)
       비트 2     = BOFF (버스오프)
       비트 6~4   = LEC  (마지막 오류 코드)
       비트 23~16 = TEC  (송신 오류 카운터)
       비트 31~24 = REC  (수신 오류 카운터)
     [주의] TEC 가 아래쪽(16비트), REC 가 위쪽(24비트)이다. 순서를 바꿔 쓰면
     "보내다 난 오류"와 "받다가 난 오류"를 통째로 뒤바꿔 읽게 되어
     원인을 정반대로 짚게 되므로 반드시 이대로 두어야 한다. */
  g_diag_can_ewgf = (uint8_t)( esr        & 0x1u);
  g_diag_can_epvf = (uint8_t)((esr >> 1)  & 0x1u);
  g_diag_can_boff = (uint8_t)((esr >> 2)  & 0x1u);
  g_diag_can_lec  = (uint8_t)((esr >> 4)  & 0x7u);
  g_diag_can_tec  = (uint8_t)((esr >> 16) & 0xFFu);
  g_diag_can_rec  = (uint8_t)((esr >> 24) & 0xFFu);

  /* HAL 계층이 따로 모아 둔 오류값도 같이 남겨 둔다 */
  g_diag_can_hal_err = HAL_CAN_GetError(&hcan);
}

/* keep this function's logic in sync with vehicle/Core/Src/freertos.c's equivalent recovery helper */
/* The one intended difference: vehicle throttles real Stop/Start to ~1/sec via a busOffRetryTick counter because
   StartCanTxTask calls it every 100ms, while StartDefaultTask here already paces at ~1s with osDelay(1000). */
/**
  * @brief  버스오프에 빠졌으면 CAN 을 껐다 켜서 되살려 본다.
  *
  *         이 보드는 AutoBusOff 가 꺼져 있어서(CubeMX 에서 AutoBusOff = DISABLE),
  *         버스오프에 빠져도 하드웨어가 알아서 빠져나오지 않는다.
  *         그래서 소프트웨어가 직접 "초기화 요청"을 걸었다가 풀어 주어야 한다.
  *         HAL_CAN_Stop() 이 초기화 요청을 걸고 HAL_CAN_Start() 가 그것을 푸는데,
  *         이 과정을 거쳐야 컨트롤러가 버스가 조용해지기를 기다렸다가 다시 합류한다.
  *
  *         [먼저 손잡이 상태를 확인해야 하는 이유]
  *         HAL_CAN_Stop() 은 손잡이 상태가 LISTENING 일 때만, HAL_CAN_Start() 는
  *         READY 일 때만 실제로 하드웨어를 건드린다. 그 밖의 상태에서는 하드웨어를
  *         건드리지도 않고 그 자리에서 곧바로 오류만 돌려준다.
  *         그래서 시도할 수 있는 상태인지 먼저 보고, 아니면 수신 인터럽트를
  *         끄지도 않고 그대로 물러난다. 여기서는 사이에 낀 Stop/Start 가 없어
  *         막아 줄 구간 자체가 없기 때문이다.
  *         다만 물러나면서 g_diag_can_notify_ok 는 0 으로 내린다.
  *         인터럽트 설정을 그대로 두는 것과, 지금 수신을 믿을 수 있다고
  *         표시해 두는 것은 별개의 이야기이기 때문이다(그 갈래의 설명 참고).
  *
  *         [횟수는 온전히 성공했을 때만 센다]
  *         g_diag_can_recover_cnt 는 "되살아난 횟수"다. 시도만 하고 실패한 것까지
  *         세면 값이 계속 오르는 것을 보고 "열심히 복구되는 중"으로 잘못 읽는다.
  *
  *         [포기하지 않는다]
  *         한 번 실패했다고 다음 시도를 막지 않는다. 상대 노드가 뒤늦게 켜지면
  *         그때부터 다시 붙을 수 있어야 하기 때문이다.
  *
  *         [실패를 삼키지 않는다]
  *         막혔거나 실패했으면 g_diag_can_stuck 에 그 사실을 남긴다.
  *         이 값은 지금 형편을 그대로 비추는 값이라, 나중에 온전히 성공하면
  *         다시 0 이 된다. 다만 알림은 0 에서 1 로 바뀌는 순간에만 찍는다.
  *         1초마다 도는 고리라서 매번 찍으면 UART 가 같은 말로 뒤덮이기 때문이다.
  *
  * @retval 0 = 버스오프가 아니어서 할 일이 없었음,
  *         1 = 이번에 온전히 되살아났음,
  *         2 = 시도했지만(또는 시도조차 못 하고) 실패했음
  */
static uint8_t Can_TryBusOffRecover(void)
{
  const char *fail_why  = "";
  uint8_t     recovered = 0u;

  if (g_diag_can_boff == 0u)
  {
    return 0u;
  }

  if (hcan.State != HAL_CAN_STATE_LISTENING)
  {
    /* 멈추기(Stop)를 받아 주지 않는 상태다. 시도 자체가 불가능하다.

       [수신 인터럽트(하드웨어)는 여전히 건드리지 않는다]
       여기서 꺼 버리면 다시 켤 길이 없어 수신이 영영 막힌다. 아래 갈래에서는
       Stop/Start 를 앞뒤로 감싼 뒤 반드시 다시 켜 주지만, 이 갈래에는 감쌀
       구간도 다시 켜 줄 자리도 없다. 그러니 하드웨어 설정은 그대로 둔다.
       이 판단은 예전 그대로다.

       [그런데 진단 플래그는 내린다 - 예전에 이 둘을 한 덩어리로 본 것이 잘못이었다]
       "수신 인터럽트를 켜 두었는가(하드웨어 설정)"와 "지금 수신을 믿어도 되는가
       (진단 표시)"는 서로 다른 이야기다. 예전에는 인터럽트를 안 건드린다는 이유로
       플래그까지 손대지 않았는데, 그러면 이 함수 바깥의 다른 원인으로 CAN 상태가
       망가졌을 때 g_diag_can_notify_ok 가 마지막에 적힌 값("정상")에 그대로
       멈춰 앉아 버린다. 손잡이가 LISTENING 조차 아니라면 인터럽트 설정이 어떻든
       실제로는 프레임이 올라오지 않는다. 플래그는 이 함수가 무엇을 했는지가 아니라
       하드웨어의 지금 형편을 비추어야 하므로 0 으로 내린다.
       (vehicle 쪽 같은 갈래도 같은 이유로 자기 플래그를 여기서 내린다) */
    g_diag_can_notify_ok = 0u;
    fail_why = "CAN 손잡이가 Stop/Start 를 받지 않습니다";
  }
  else
  {
    HAL_StatusTypeDef stop_st;    /* HAL_CAN_Stop() 이 돌려준 결과 */
    HAL_StatusTypeDef start_st;   /* HAL_CAN_Start() 가 돌려준 결과 */

    printf("[CAN] 버스오프 감지 - 복구를 시도합니다\r\n");

    /* 수신 인터럽트를 잠시 꺼 둔다. Can_LoopbackSelfTest() 가 하는 것과 같은 이유다.
       수신 인터럽트 콜백은 여기와 똑같은 hcan 손잡이를 건드리는데,
       Stop/Start 로 손잡이 상태가 바뀌는 도중에 그 일이 겹치면
       서로 어긋난 값을 보게 되므로 전환이 끝날 때까지 막아 둔다. */
    (void)HAL_CAN_DeactivateNotification(&hcan, CAN_IT_RX_FIFO0_MSG_PENDING);
    g_diag_can_notify_ok = 0u;

    stop_st = HAL_CAN_Stop(&hcan);

    /* 멈추기가 성공했을 때에만 시작을 부른다. 그렇지 않은 채로 불러 봐야
       하드웨어를 건드리지도 못하고 실패만 하므로, 아예 부르지 않고 실패로 적는다.

       [손잡이 상태를 함께 보던 조건을 덜어낸 이유]
       HAL_CAN_Start() 가 실제로 일하는 조건은 State 가 READY 인 것이다. 그런데
       벤더 HAL 소스(stm32f1xx_hal_can.c 의 HAL_CAN_Stop())를 보면, HAL_OK 를
       돌려주는 길은 State 를 HAL_CAN_STATE_READY 로 적어 넣은 바로 다음 줄
       하나뿐이다. 나머지 두 길(대기 시간 초과, 애초에 LISTENING 이 아님)은 모두
       HAL_ERROR 로 빠진다. 그러니 stop_st == HAL_OK 라는 사실 자체가 곧
       "지금 READY 다"라는 보증이다.
       함께 보던 (hcan.State == HAL_CAN_STATE_READY) 는 늘 참일 수밖에 없는
       중복 조건이었고, 남겨 두면 읽는 사람에게 "이 둘이 어긋나는 경우가 있나"
       하는 헛된 의심만 남긴다. 그래서 덜어냈다. */
    if (stop_st == HAL_OK)
    {
      start_st = HAL_CAN_Start(&hcan);
    }
    else
    {
      start_st = HAL_ERROR;
    }

    if (stop_st != HAL_OK)
    {
      fail_why = "멈추기(Stop)가 되지 않습니다";
    }
    else if (start_st != HAL_OK)
    {
      fail_why = "다시 시작(Start)이 되지 않습니다";
    }
    else
    {
      recovered = 1u;
    }

    /* 우리가 껐던 수신 인터럽트는 성공이든 실패든 반드시 다시 켠다.
       실패했다고 꺼 둔 채로 두면, 나중에 버스가 알아서 되살아나도
       프레임을 하나도 못 받는 꼴이 된다.
       손잡이가 ERROR 로 굳었다면 이 켜기도 같은 이유로 실패하지만,
       그때는 어차피 수신 자체가 안 되는 상태라 이로써 잃는 것은 없다. */
    if (HAL_CAN_ActivateNotification(&hcan, CAN_IT_RX_FIFO0_MSG_PENDING) == HAL_OK)
    {
      g_diag_can_notify_ok = 1u;
    }
    else
    {
      g_diag_can_notify_ok = 0u;
    }
  }

  if (recovered != 0u)
  {
    g_diag_can_started = 1u;
    /* 이번 시도가 온전히 성공했으니 지금은 막힌 상태가 아니다.
       이 값은 지난 일을 붙박이로 남기는 표시가 아니라 지금 형편을
       비추는 값이라서, 성공했으면 반드시 0 으로 되돌려야 한다. */
    g_diag_can_stuck = 0u;
    g_diag_can_recover_cnt++;

    printf("[CAN] 버스오프에서 복구했습니다 (누적 성공 %lu회)\r\n",
           (unsigned long)g_diag_can_recover_cnt);
    return 1u;
  }

  g_diag_can_started = 0u;

  if (g_diag_can_stuck == 0u)
  {
    g_diag_can_stuck = 1u;
    printf("[CAN] 버스오프 복구 실패 : %s (상태값 %u)\r\n",
           fail_why, (unsigned int)hcan.State);
  }

  return 2u;
}

/**
  * @brief  CAN 컨트롤러 자체가 멀쩡한지 확인하는 루프백 자기진단.
  *
  *         루프백 모드는 내보낸 신호를 칩 안에서 곧바로 자기 수신부로
  *         되돌려 넣는 시험 모드다. 이때 수신 핀(PA11)에서 들어오는 실제 신호는
  *         아예 무시하므로, 트랜시버가 안 붙어 있든 배선이 끊겼든 상관이 없다.
  *         그래서 이 시험이 성공하면 클럭·비트타이밍(통신 속도)·필터·인터럽트 같은
  *         MCU 안쪽 설정이 전부 정상이라는 뜻이 되고,
  *         남은 원인은 바깥(트랜시버·배선·종단저항·상대 노드)뿐으로 좁혀진다.
  */
static void Can_LoopbackSelfTest(void)
{
  CAN_RxHeaderTypeDef rx_header = {0};
  uint8_t             tx_data[2];
  uint8_t             rx_data[8] = {0u};
  uint32_t            waited_ms  = 0u;
  uint8_t             match_found = 0u;  /* 내가 보낸 시험용 프레임과 같은 것을 받았으면 1 */
  uint8_t             rx_fail     = 0u;  /* 수신함에서 꺼내는 것 자체가 실패했으면 1 */
  uint8_t             other_seen  = 0u;  /* 시험용이 아닌 남의 프레임을 하나라도 받았으면 1 */
  /* [match_found 와 rx_fail 을 하나로 합치지 않는 이유]
     꺼내기가 실패해도 고리를 계속 돌게 고쳤기 때문에, 한 번의 시험 안에서
     rx_fail 이 먼저 서고 그 뒤에 match_found 까지 서는 일이 실제로 일어난다.
     둘은 더 이상 서로를 밀어내는 사이가 아니라 각각 따로 일어난 사실이므로,
     한 변수에 몰아넣으면 "미끄러졌지만 결국 성공한" 경우를 표현할 길이 없어진다. */

  tx_data[0] = 0xABu;
  tx_data[1] = 0xCDu;

  printf("[CAN 자가진단] 루프백 시험을 시작합니다 (바깥 배선과 무관한 내부 시험)\r\n");

  /* ---------- 0단계 : 수신 인터럽트를 잠시 꺼 둔다 ----------
     [이 단계가 없으면 시험이 통째로 헛돈다]
     수신 인터럽트가 켜져 있으면, 되돌아온 시험용 프레임을 인터럽트가 먼저
     낚아채서 수신함(FIFO)을 비워 버린다. 그러면 아래에서 아무리 수신함을
     들여다봐도 늘 비어 있어서, 멀쩡한데도 "수신 타임아웃(3)"이라는
     엉뚱한 결과가 나온다.
     그리고 인터럽트가 가져가 버리면 시험용 프레임이 실제 수신 개수
     (g_diag_can_total)에 섞여 들어가 통계까지 더럽힌다.
     HAL_CAN_Stop() 이나 HAL_CAN_Init() 은 인터럽트 설정을 건드리지 않으므로,
     이렇게 직접 꺼 주어야 한다. */
  (void)HAL_CAN_DeactivateNotification(&hcan, CAN_IT_RX_FIFO0_MSG_PENDING);
  g_diag_can_notify_ok = 0u;

  /* ---------- 1단계 : 루프백 모드로 바꾼다 ----------
     MX_CAN_Init() 이 이미 정상 모드로 초기화해 둔 상태이므로,
     일단 멈춘 뒤 모드만 바꿔서 다시 초기화한다.
     여기서의 멈춤은 실패해도 그냥 넘어간다. 부팅 때 HAL_CAN_Start() 가
     실패했다면 아직 "멈출 것이 없는" 상태라 오류를 돌려주는데,
     그래도 다시 초기화하는 데에는 지장이 없기 때문이다. */
  (void)HAL_CAN_Stop(&hcan);
  g_diag_can_started = 0u;

  hcan.Init.Mode = CAN_MODE_LOOPBACK;

  if (HAL_CAN_Init(&hcan) != HAL_OK)
  {
    /* 아직 프레임을 내보내는 데까지 가지도 못했으므로 송신 실패로 묶는다 */
    g_diag_can_loopback = 2u;
    printf("[CAN 자가진단] 결과 2 : 루프백 모드 초기화에 실패했습니다\r\n");
  }
  else if (Can_SetAcceptAllFilter() == 0u)
  {
    g_diag_can_loopback = 2u;
    printf("[CAN 자가진단] 결과 2 : 루프백용 필터 설정에 실패했습니다\r\n");
  }
  else if (HAL_CAN_Start(&hcan) != HAL_OK)
  {
    g_diag_can_loopback = 2u;
    printf("[CAN 자가진단] 결과 2 : 루프백 모드 시작에 실패했습니다\r\n");
  }
  else
  {
    /* ---------- 2단계 : 시험용 프레임을 하나 내보낸다 ----------
       0x7FF 는 실제 통신에 안 쓰는 값이라 시험용으로 골랐다. */
    if (Can_Send(0x7FFu, tx_data, 2u) == 0u)
    {
      g_diag_can_loopback = 2u;
      printf("[CAN 자가진단] 결과 2 : 송신함에 프레임을 넣지 못했습니다\r\n");
    }
    else
    {
      /* ---------- 3단계 : 최대 100ms 동안 되돌아오기를 기다린다 ----------
         이 함수는 FreeRTOS 스케줄러가 이미 돌고 있는 태스크 안에서 불리므로
         HAL_Delay() 가 아니라 osDelay() 를 써야 한다.
         HAL_Delay() 는 기다리는 동안 자리를 안 내주고 붙잡고 있어서
         다른 태스크가 전부 멈춰 버린다.

         [맨 앞의 한 개만 보고 판정하면 안 되는 이유]
         지금 모드는 루프백이지만 silent 는 아니다. 그래서 수신 핀으로 들어오는
         바깥 노드의 진짜 프레임도 그대로 수신함에 쌓인다.
         내가 보낸 시험용 프레임보다 남의 프레임이 먼저 들어와 있을 수 있는데,
         맨 앞의 것 하나만 꺼내 대조하면 CAN 하드웨어가 멀쩡한데도
         "데이터 불일치" 라는 엉뚱한 결과가 나온다.
         그래서 하나씩 꺼내 보면서, 내 것이 나올 때까지 남의 것은 버리고 계속 기다린다.
         남의 프레임을 버린 뒤에도 아래 osDelay(1) 로 내려가 waited_ms 가 오르므로,
         전체로 기다리는 시간은 예전과 똑같이 100ms 를 넘지 않는다. */
      while (waited_ms < 100u)
      {
        if (HAL_CAN_GetRxFifoFillLevel(&hcan, CAN_RX_FIFO0) > 0u)
        {
          if (HAL_CAN_GetRxMessage(&hcan, CAN_RX_FIFO0, &rx_header, rx_data) != HAL_OK)
          {
            /* 꺼내기가 한 번 미끄러졌다고 시험을 통째로 접지 않는다.
               바로 뒤에 진짜 시험용 프레임이 줄 서 있을 수도 있는데 여기서
               빠져나가면, 멀쩡한 CAN 셀을 고장으로 적어 버리게 된다.
               그래서 "그런 일이 있었다"는 사실만 남겨 두고(아래 판정에서
               결과 5 로 쓰인다) 남은 시간만큼 계속 기다린다.

               [break 도 continue 도 아닌, 아래로 흘려보내는 이유]
               break 면 위에 적은 그대로 100ms 예산을 통째로 버리게 된다.
               continue 는 더 나쁘다. 바로 아래 osDelay(1) 과 waited_ms++ 를
               건너뛰므로, 꺼내기가 계속 실패하는 상황에서는 100ms 라는 제한이
               영영 차지 않는다. 그러면 이 태스크가 자리를 내주지 않고 그 자리에서
               CPU 를 갉아먹으며 맴돌아, 부팅이 아예 더 나아가지 못한다.
               아무것도 하지 않고 아래로 떨어뜨리는 것이 유일하게 맞는 선택이다. */
            rx_fail = 1u;
          }
          else if ((rx_header.IDE   == CAN_ID_STD) &&
                   (rx_header.StdId == 0x7FFu)     &&
                   (rx_header.DLC   == 2u)         &&
                   (rx_data[0]      == 0xABu)      &&
                   (rx_data[1]      == 0xCDu))
          {
            match_found = 1u;
            break;
          }
          else
          {
            other_seen = 1u;   /* 남의 프레임 - 버리고 계속 기다린다 */
          }
        }

        osDelay(1);
        waited_ms++;
      }

      /* ---------- 4단계 : 기다린 결과를 판정한다 ----------
         적어 둔 순서가 곧 우선순위다. 꺼내기가 실패해도 계속 기다리도록
         고친 뒤로는 표시 여러 개가 한꺼번에 서 있을 수 있어서,
         어느 것을 먼저 보느냐가 결과를 가른다. */
      if (match_found != 0u)
      {
        /* 도중에 꺼내기가 한 번 미끄러졌더라도(rx_fail 이 서 있더라도) 끝내
           내 시험용 프레임을 받아 냈다면, 확인하려던 것 - 클럭·비트타이밍·
           필터·수신 경로 - 은 전부 제대로 도는 것이다. 그러니 성공이 실패
           표시를 이긴다. 이 순서가 뒤집히면 잠깐의 딸꾹질 하나 때문에
           멀쩡한 보드가 고장으로 적힌다. */
        g_diag_can_loopback = 1u;
        printf("[CAN 자가진단] 결과 1 : 성공 - MCU 안쪽 CAN 설정은 정상입니다\r\n");
      }
      else if (rx_fail != 0u)
      {
        /* 예전에는 이 경우도 3 으로 적었다. 그래서 "아무것도 안 들어왔다"와
           "들어오기는 했는데 꺼내지 못했다"가 진단 화면에서 똑같아 보였다.
           앞은 배선·상대 노드를 봐야 하고 뒤는 수신함 다루는 쪽을 봐야 하는,
           짚을 곳이 아주 다른 이야기라 번호를 따로 준다. */
        g_diag_can_loopback = 5u;
        printf("[CAN 자가진단] 결과 5 : 드레인 도중 수신함에서 프레임을 꺼내지 못했습니다 (시험용 프레임도 끝내 되돌아오지 않았습니다)\r\n");
      }
      else if (other_seen == 0u)
      {
        /* 수신함에 아무것도 들어오지 않았다 */
        g_diag_can_loopback = 3u;
        printf("[CAN 자가진단] 결과 3 : 100ms 안에 되돌아오지 않았습니다\r\n");
      }
      else
      {
        /* 남의 프레임은 들어왔는데 내 시험용 프레임만 끝내 안 왔다 */
        g_diag_can_loopback = 4u;
        printf("[CAN 자가진단] 결과 4 : 100ms 안에 시험용 프레임(0x7FF)이 되돌아오지 않았습니다 (다른 프레임만 들어왔습니다)\r\n");
      }
    }
  }

  /* ---------- 5단계 : 반드시 정상 모드로 되돌린다 ----------
     [가장 중요한 단계]
     이 되돌리기가 한 군데라도 실패하면 이후 실제 통신이 영영 되지 않는다.
     그래서 단계마다 결과를 하나하나 확인하고,
     전부 성공했을 때에만 g_diag_can_restore_ok 를 1 로 둔다.
     위쪽 시험이 어떤 결과로 끝났든(성공이든 실패든) 이 되돌리기는
     if/else 바깥에 두어 항상 실행되도록 했다. */
  g_diag_can_restore_ok = 0u;

  (void)HAL_CAN_Stop(&hcan);
  g_diag_can_started = 0u;

  hcan.Init.Mode = CAN_MODE_NORMAL;

  if (HAL_CAN_Init(&hcan) != HAL_OK)
  {
    printf("[CAN 자가진단] 되돌리기 실패 : 정상 모드 초기화가 안 됩니다\r\n");
  }
  else if (Can_SetAcceptAllFilter() == 0u)
  {
    printf("[CAN 자가진단] 되돌리기 실패 : 정상 모드 필터 재설정이 안 됩니다\r\n");
  }
  else if (HAL_CAN_Start(&hcan) != HAL_OK)
  {
    printf("[CAN 자가진단] 되돌리기 실패 : 정상 모드 시작이 안 됩니다\r\n");
  }
  else
  {
    g_diag_can_started = 1u;

    if (HAL_CAN_ActivateNotification(&hcan, CAN_IT_RX_FIFO0_MSG_PENDING) != HAL_OK)
    {
      printf("[CAN 자가진단] 되돌리기 실패 : 수신 인터럽트를 다시 켜지 못했습니다\r\n");
    }
    else
    {
      g_diag_can_notify_ok   = 1u;
      g_diag_can_restore_ok  = 1u;   /* 모든 단계가 성공했다 */
      printf("[CAN 자가진단] 정상 모드로 되돌렸습니다 (이제부터 실제 수신을 기다립니다)\r\n");
    }
  }
}

/**
  * @brief  IMU 자세 추정 태스크.
  *
  *         20ms(=50Hz) 마다 MPU-9255 에서 가속도와 자이로를 읽어
  *         상보필터를 한 걸음씩 전진시키고, 그 가운데 다섯 번에 한 번
  *         (=100ms) 씩 지금 자세를 CAN 프레임 0x120 으로 내보낸다.
  *
  *         [센서는 50Hz 로 읽으면서 송신은 10Hz 로 낮추는 이유]
  *         자이로 적분은 촘촘할수록 정확해지므로 읽기는 자주 해야 한다.
  *         하지만 자세라는 값 자체는 그렇게 빨리 변하지 않아서
  *         받는 쪽에 100ms 마다 알려 주는 것으로 충분하다.
  *         50Hz 로 그대로 내보내면 버스만 다섯 배로 붐빈다.
  * @param  argument: 쓰지 않는다
  * @retval None
  */
void StartImuTask(void const * argument)
{
  uint8_t  data[8];
  int16_t  rollTenths;    /* 좌우 기울기를 0.1도 단위 정수로 바꾼 값 */
  int16_t  pitchTenths;   /* 앞뒤 기울기를 0.1도 단위 정수로 바꾼 값 */
  int16_t  yawTenths;     /* 방위각을 0.1도 단위 정수로 바꾼 값 */
  /* [static 을 붙이지 않는 이유]
     이 태스크는 딱 한 번 들어와서 영영 돌아 나가지 않는다. 그래서 그냥 지역
     변수로 두어도 값은 고리를 도는 내내 그대로 이어진다. static 을 붙이면
     얻는 것은 없이 .bss 만 차지한다. */
  uint8_t  txDivider    = 0u;   /* IMU_TX_DIVIDER 번에 한 번만 보내려고 세는 값 */
  uint8_t  frameCounter = 0u;   /* 보낸 프레임에 붙이는 돌림 번호 */

  /* ---------- 부팅 때의 I2C 사용이 끝나기를 먼저 기다린다 ----------
     StartDefaultTask 가 hi2c1 을 다 쓰고 나서 넘겨주는 신호다.
     (겹치면 왜 위험한지는 파일 위쪽 s_i2cScanDoneSem 선언부에 적어 두었다.)

     [Mpu9255_Init() 바로 앞이 아니라 printf 보다 먼저 기다리는 이유]
     I2C 를 실제로 건드리는 것은 Mpu9255_Init() 부터이니, 기다림을 그 바로 앞에
     두어도 버스는 안전하다. 그런데도 아래 두 줄의 printf 보다 앞에 두었다.
       1) 여기서 찍는 두 줄이 스캔 결과 127줄 사이에 끼어들어 뒤섞이면,
          정작 봐야 할 스캔 출력이 읽기 어려워진다. 출력이 섞이는 것은
          진단용 화면에서 생각보다 큰 손해다.
       2) 아래 "자이로 영점을 재는 동안(약 1초) 보드를 움직이지 마세요" 는
          지금 당장 움직이지 말라는 말이다. 스캔이 끝나기 1.5초쯤 전에 미리
          찍어 두면, 정작 영점을 재는 순간에는 그 경고가 화면 저 위로 밀려나
          아무도 지키지 않는 거짓말이 된다. 경고는 실제로 재기 직전에 나와야 한다.

     [손잡이가 NULL 일 때의 대비책이 꼭 있어야 하는 이유]
     힙이 6144바이트뿐이라 세마포어를 만들지 못하는 일이 생길 수 있다. 그런데
     osSemaphoreWait() 는 NULL 을 받으면 기다리지 않고 osErrorParameter 만 그
     자리에서 돌려준다. 그러면 막으려던 겹침이 아무 소리도 내지 않고 그대로
     되살아난다. 그래서 그때는 StartDefaultTask 가 세워 주는 g_diag_scan_done 을
     10ms 마다 들여다보며 같은 순서를 지킨다. 10ms 는 부팅 때 한 번뿐인 기다림이라
     더 촘촘히 볼 이유가 없고, 그동안 다른 태스크에 자리를 내주는 값이다. */
  if (s_i2cScanDoneSem != NULL)
  {
    (void)osSemaphoreWait(s_i2cScanDoneSem, osWaitForever);
  }
  else
  {
    while (g_diag_scan_done == 0u)
    {
      osDelay(10);
    }
  }

  printf("[IMU] 자세 추정을 시작합니다 (%ums 마다 표본, %ums 마다 CAN 0x%03X 송신)\r\n",
         (unsigned int)IMU_TASK_PERIOD_MS,
         (unsigned int)(IMU_TASK_PERIOD_MS * IMU_TX_DIVIDER),
         (unsigned int)CAN_ID_IMU_ATTITUDE);
  printf("[IMU] 자이로 영점을 재는 동안(약 1초) 보드를 움직이지 마세요\r\n");

  /* ---------- 센서를 깨우고 설정한 뒤 자이로 영점까지 잰다 (딱 한 번) ----------
     이 안에서 약 1초 동안 osDelay() 로 쉬어 가며 200번을 읽으므로,
     그동안 다른 태스크(CAN 수신 출력 등)는 정상으로 돌아간다.
     위에서 신호를 받고 내려온 자리라 I2C 스캔은 이미 끝나 있다.
     즉 지금 이 순간 hi2c1 을 쓰는 것은 이 태스크 하나뿐이다. */
  if (Mpu9255_Init() != 0u)
  {
    printf("[IMU] 준비 완료 : WHO_AM_I=0x%02X, 자이로 영점 측정을 마쳤습니다\r\n",
           (unsigned int)Mpu9255_GetWhoAmI());
  }
  else
  {
    /* 일부 단계가 실패해도 태스크를 멈추지는 않는다.
       (예전에는 여기 실패를 "I2C 가 잠깐 겹쳐서"로 설명했는데, 이제 버스를
        넘겨받고 나서 부르는 자리라 겹침은 원인에서 빠진다. 남은 원인은
        배선이 잠깐 접촉 불량이거나 센서가 아직 덜 깨어난 쪽이고,
        그런 것들도 대개 곧 정상으로 돌아온다.)
       설령 계속 실패하더라도 상태 바이트의 0번 비트가 0 으로 나가므로
       받는 쪽이 "이 각도는 믿으면 안 된다"를 스스로 알아챌 수 있다. */
    printf("[IMU] 준비 중 일부 단계가 실패했습니다 : WHO_AM_I=0x%02X, 영점측정=%u\r\n",
           (unsigned int)Mpu9255_GetWhoAmI(),
           (unsigned int)Mpu9255_IsCalibrated());
  }

  /* Infinite loop */
  for(;;)
  {
    osDelay(IMU_TASK_PERIOD_MS);

    /* 표본 한 번 + 상보필터 한 걸음.
       읽기에 실패하면 0 을 돌려주는데, 그때는 각도가 직전 값 그대로 남는다.
       한두 번 놓친 것으로 자세가 크게 어긋나지는 않으므로 그냥 넘어간다. */
    (void)Mpu9255_Update();

    txDivider++;

    if (txDivider >= IMU_TX_DIVIDER)
    {
      txDivider = 0u;

      /* ================= CAN 0x120 IMU_ATTITUDE 8바이트 배치 =================
           바이트 0 : 좌우 기울기(roll)  상위 8비트
           바이트 1 : 좌우 기울기(roll)  하위 8비트
           바이트 2 : 앞뒤 기울기(pitch) 상위 8비트
           바이트 3 : 앞뒤 기울기(pitch) 하위 8비트
           바이트 4 : 방위각(yaw)        상위 8비트
           바이트 5 : 방위각(yaw)        하위 8비트
           바이트 6 : 상태 비트 (0번 비트 = 자이로 영점 측정 완료, 나머지는 0)
           바이트 7 : 돌림 번호 (보낼 때마다 1씩 오르고 256에서 0으로 돌아온다)

         각도는 0.1도를 한 칸으로 하는 부호 있는 16비트 값이고,
         큰 자리를 앞에 두는 빅엔디언으로 싣는다.
         예) -12.3도 -> -123 -> 0xFF 0x85

         [yaw 를 어디까지 믿어야 하는가]
         나침반(AK8963)은 여전히 읽지 않는다. 그래서 이 방위각은 자이로 Z축을
         적분하기만 한 값이고, 되잡아 줄 절대 기준이 없어 시간이 지날수록
         흘러간다. 받는 쪽은 "이번 회전에서 몇 도 돌았나" 처럼 짧은 구간의
         차이로만 써야 하고, 몇 분 뒤의 값을 절대 방위로 믿어서는 안 된다.

         [돌림 번호를 왜 싣는가]
         받는 쪽에서 번호가 1씩 오르지 않고 건너뛰면 그 사이 프레임이
         빠졌다는 뜻이다. 송신함이 차서 한 차례 거른 경우도
         이 번호로 드러난다.

         ※ 받는 쪽(vehicle)이 이 표를 그대로 보고 풀어내므로,
            한 칸이라도 순서를 바꾸면 양쪽이 통째로 어긋난다. */

      rollTenths  = (int16_t)(Mpu9255_GetRollDeg()  * 10.0f);
      pitchTenths = (int16_t)(Mpu9255_GetPitchDeg() * 10.0f);
      /* 드라이버가 방위각을 -180 ~ +180 안으로 이미 감아 두고 내보내므로,
         여기 들어오는 값은 아무리 커도 1800 이다. int16_t 에 넉넉히 들어가서
         이 층에서 따로 잘라 낼 일이 없다. */
      yawTenths   = (int16_t)(Mpu9255_GetYawDeg()   * 10.0f);

      /* 부호 있는 값을 오른쪽으로 밀 때의 동작은 표준이 딱 정해 두지 않았다.
         그래서 부호 없는 형으로 한 번 바꾼 뒤에 민다.
         두 값 모두 같은 비트를 담고 있으므로 실제로 나가는 바이트는 똑같지만,
         이렇게 두면 컴파일러가 달라져도 결과가 흔들리지 않는다. */
      data[0] = (uint8_t)(((uint16_t)rollTenths  >> 8) & 0xFFu);
      data[1] = (uint8_t)( (uint16_t)rollTenths        & 0xFFu);
      data[2] = (uint8_t)(((uint16_t)pitchTenths >> 8) & 0xFFu);
      data[3] = (uint8_t)( (uint16_t)pitchTenths       & 0xFFu);
      data[4] = (uint8_t)(((uint16_t)yawTenths   >> 8) & 0xFFu);
      data[5] = (uint8_t)( (uint16_t)yawTenths         & 0xFFu);
      data[6] = (uint8_t)(Mpu9255_IsCalibrated() & 0x01u);
      data[7] = frameCounter;

      /* 돌림 번호는 "실제로 내보낸 프레임"에만 붙어야 한다.
         송신함에 넣는 데까지 성공했을 때에만 다음 번호로 넘긴다.
         Can_Send() 는 송신함에 빈자리가 없으면 기다리지 않고 0 을 돌려주는데,
         그렇게 한 차례 거른 것은 받는 쪽이 이 번호가 건너뛴 것으로 알아챈다.
         uint8_t 라서 255 다음은 저절로 0 으로 돌아온다. */
      if (Can_Send(CAN_ID_IMU_ATTITUDE, data, 8u) != 0u)
      {
        frameCounter++;
      }
    }
  }
}
/* USER CODE END Application */
